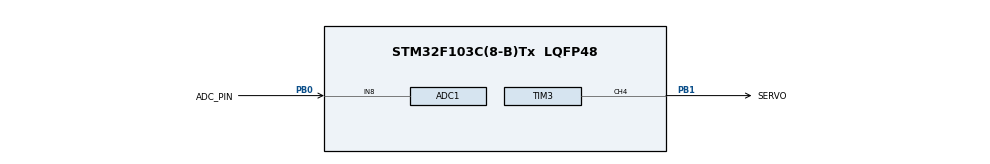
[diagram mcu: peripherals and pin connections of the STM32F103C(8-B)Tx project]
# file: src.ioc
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ADC1.Channel-0\#ChannelRegularConversion=ADC_CHANNEL_8
ADC1.NbrOfConversionFlag=1
ADC1.Rank-0\#ChannelRegularConversion=1
ADC1.SamplingTime-0\#ChannelRegularConversion=ADC_SAMPLETIME_55CYCLES_5
ADC1.master=1
Mcu.Family=STM32F1
Mcu.Name=STM32F103C(8-B)Tx
Mcu.Package=LQFP48
NVIC.PriorityGroup=NVIC_PRIORITYGROUP_4
NVIC.TIM2_IRQn=true\:2\:0\:true\:false\:true\:true\:true\:true
PA13.Mode=Serial_Wire
PA13.Signal=SYS_JTMS-SWDIO
PA14.Mode=Serial_Wire
PA14.Signal=SYS_JTCK-SWCLK
PB0.GPIO_Label=ADC_PIN
PB0.Signal=SharedAnalog_PB0
PB1.GPIO_Label=SERVO
PB1.Signal=S_TIM3_CH4
PD0-OSC_IN.Mode=HSE-External-Oscillator
PD0-OSC_IN.Signal=RCC_OSC_IN
PD1-OSC_OUT.Mode=HSE-External-Oscillator
PD1-OSC_OUT.Signal=RCC_OSC_OUT
ProjectManager.HeapSize=0x200
ProjectManager.StackSize=0x400
ProjectManager.TargetToolchain=EWARM V8.32
RCC.ADCPresc=RCC_ADCPCLK2_DIV6
RCC.AHBFreq_Value=72000000
RCC.APB1CLKDivider=RCC_HCLK_DIV2
RCC.APB1Freq_Value=36000000
RCC.APB1TimFreq_Value=72000000
RCC.APB2Freq_Value=72000000
RCC.APB2TimFreq_Value=72000000
RCC.HCLKFreq_Value=72000000
RCC.PLLMUL=RCC_PLL_MUL9
RCC.PLLSourceVirtual=RCC_PLLSOURCE_HSE
RCC.SYSCLKFreq_VALUE=72000000
RCC.SYSCLKSource=RCC_SYSCLKSOURCE_PLLCLK
RCC.USBFreq_Value=72000000
SH.S_TIM3_CH4.0=TIM3_CH4,PWM Generation4 CH4
SH.SharedAnalog_PB0.0=GPIO_Analog
SH.SharedAnalog_PB0.1=ADC1_IN8,IN8
TIM2.Period=999
TIM2.Prescaler=71
TIM3.AutoReloadPreload=TIM_AUTORELOAD_PRELOAD_ENABLE
TIM3.Channel-PWM\ Generation4\ CH4=TIM_CHANNEL_4
TIM3.OCFastMode_PWM-PWM\ Generation4\ CH4=TIM_OCFAST_ENABLE
TIM3.Period=19999
TIM3.Prescaler=71
TIM3.Pulse-PWM\ Generation4\ CH4=1500
VP_TIM2_VS_ClockSourceINT.Mode=Internal
VP_TIM3_VS_ClockSourceINT.Mode=Internal
board=custom

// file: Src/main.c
  /* USER CODE BEGIN Header */
  /**
    ******************************************************************************
    * @file           : main.c
    * @brief          : Main program body
    ******************************************************************************
    * @attention
    *
    * Copyright (c) 2026 STMicroelectronics.
    * All rights reserved.
    *
    * This software is licensed under terms that can be found in the LICENSE file
    * in the root directory of this software component.
    * If no LICENSE file comes with this software, it is provided AS-IS.
    *
    ******************************************************************************
    */
    #include "display.h"
  /* USER CODE END Header */
  /* Includes ------------------------------------------------------------------*/
  #include "main.h"

  /* Private includes ----------------------------------------------------------*/

  /* Private typedef -----------------------------------------------------------*/

  /* Private define ------------------------------------------------------------*/

  /* Private macro -------------------------------------------------------------*/

  /* Private variables ---------------------------------------------------------*/
  ADC_HandleTypeDef hadc1;

  TIM_HandleTypeDef htim2;
  TIM_HandleTypeDef htim3;

  /* Private function prototypes -----------------------------------------------*/
  void SystemClock_Config(void);
  static void MX_GPIO_Init(void);
  static void MX_ADC1_Init(void);
  static void MX_TIM2_Init(void);
  static void MX_TIM3_Init(void);

  /* Private user code ---------------------------------------------------------*/

  /**
    * @brief  The application entry point.
    * @retval int
    */
  int main(void)
  {

    /* MCU Configuration--------------------------------------------------------*/

    /* Reset of all peripherals, Initializes the Flash interface and the Systick. */
    HAL_Init();

    /* Configure the system clock */
    SystemClock_Config();

    /* Initialize all configured peripherals */
    MX_GPIO_Init();
    MX_ADC1_Init();
    MX_TIM2_Init();
    MX_TIM3_Init();
    /* USER CODE BEGIN 2 */
    HAL_ADCEx_Calibration_Start(&hadc1);
    Display_Init();
    HAL_TIM_Base_Start_IT(&htim2);
    HAL_TIM_PWM_Start(&htim3, TIM_CHANNEL_4);
    /* USER CODE END 2 */

    /* Infinite loop */
    while (1)
    {

      /* USER CODE BEGIN 3 */
      HAL_ADC_Start(&hadc1);
      if (HAL_ADC_PollForConversion(&hadc1, 100) == HAL_OK)
      {
        uint32_t adc_value = HAL_ADC_GetValue(&hadc1);
        uint16_t servo_position = (adc_value * 180) / 4095;
        uint16_t pulse = ((servo_position * 2000) / 180) + 500;

        __HAL_TIM_SET_COMPARE(&htim3, TIM_CHANNEL_4, pulse);
        Display_SetNumber(servo_position);
      }
      HAL_ADC_Stop(&hadc1);
    }
    /* USER CODE END 3 */
  }

  /**
    * @brief System Clock Configuration
    * @retval None
    */
  void SystemClock_Config(void)
  {
    RCC_OscInitTypeDef RCC_OscInitStruct = {0};
    RCC_ClkInitTypeDef RCC_ClkInitStruct = {0};
    RCC_PeriphCLKInitTypeDef PeriphClkInit = {0};

    /** Initializes the RCC Oscillators according to the specified parameters
    * in the RCC_OscInitTypeDef structure.
    */
    RCC_OscInitStruct.OscillatorType = RCC_OSCILLATORTYPE_HSE;
    RCC_OscInitStruct.HSEState = RCC_HSE_ON;
    RCC_OscInitStruct.HSEPredivValue = RCC_HSE_PREDIV_DIV1;
    RCC_OscInitStruct.HSIState = RCC_HSI_ON;
    RCC_OscInitStruct.PLL.PLLState = RCC_PLL_ON;
    RCC_OscInitStruct.PLL.PLLSource = RCC_PLLSOURCE_HSE;
    RCC_OscInitStruct.PLL.PLLMUL = RCC_PLL_MUL9;
    if (HAL_RCC_OscConfig(&RCC_OscInitStruct) != HAL_OK)
    {
      Error_Handler();
    }

    /** Initializes the CPU, AHB and APB buses clocks
    */
    RCC_ClkInitStruct.ClockType = RCC_CLOCKTYPE_HCLK|RCC_CLOCKTYPE_SYSCLK
                                |RCC_CLOCKTYPE_PCLK1|RCC_CLOCKTYPE_PCLK2;
    RCC_ClkInitStruct.SYSCLKSource = RCC_SYSCLKSOURCE_PLLCLK;
    RCC_ClkInitStruct.AHBCLKDivider = RCC_SYSCLK_DIV1;
    RCC_ClkInitStruct.APB1CLKDivider = RCC_HCLK_DIV2;
    RCC_ClkInitStruct.APB2CLKDivider = RCC_HCLK_DIV1;

    if (HAL_RCC_ClockConfig(&RCC_ClkInitStruct, FLASH_LATENCY_2) != HAL_OK)
    {
      Error_Handler();
    }
    PeriphClkInit.PeriphClockSelection = RCC_PERIPHCLK_ADC;
    PeriphClkInit.AdcClockSelection = RCC_ADCPCLK2_DIV6;
    if (HAL_RCCEx_PeriphCLKConfig(&PeriphClkInit) != HAL_OK)
    {
      Error_Handler();
    }
  }

  /**
    * @brief ADC1 Initialization Function
    * @param None
    * @retval None
    */
  static void MX_ADC1_Init(void)
  {

    ADC_ChannelConfTypeDef sConfig = {0};

    /** Common config
    */
    hadc1.Instance = ADC1;
    hadc1.Init.ScanConvMode = ADC_SCAN_DISABLE;
    hadc1.Init.ContinuousConvMode = DISABLE;
    hadc1.Init.DiscontinuousConvMode = DISABLE;
    hadc1.Init.ExternalTrigConv = ADC_SOFTWARE_START;
    hadc1.Init.DataAlign = ADC_DATAALIGN_RIGHT;
    hadc1.Init.NbrOfConversion = 1;
    if (HAL_ADC_Init(&hadc1) != HAL_OK)
    {
      Error_Handler();
    }

    /** Configure Regular Channel
    */
    sConfig.Channel = ADC_CHANNEL_8;
    sConfig.Rank = ADC_REGULAR_RANK_1;
    sConfig.SamplingTime = ADC_SAMPLETIME_55CYCLES_5;
    if (HAL_ADC_ConfigChannel(&hadc1, &sConfig) != HAL_OK)
    {
      Error_Handler();
    }

  }

  /**
    * @brief TIM2 Initialization Function
    * @param None
    * @retval None
    */
  static void MX_TIM2_Init(void)
  {

    TIM_ClockConfigTypeDef sClockSourceConfig = {0};
    TIM_MasterConfigTypeDef sMasterConfig = {0};

    htim2.Instance = TIM2;
    htim2.Init.Prescaler = 71;
    htim2.Init.CounterMode = TIM_COUNTERMODE_UP;
    htim2.Init.Period = 999;
    htim2.Init.ClockDivision = TIM_CLOCKDIVISION_DIV1;
    htim2.Init.AutoReloadPreload = TIM_AUTORELOAD_PRELOAD_DISABLE;
    if (HAL_TIM_Base_Init(&htim2) != HAL_OK)
    {
      Error_Handler();
    }
    sClockSourceConfig.ClockSource = TIM_CLOCKSOURCE_INTERNAL;
    if (HAL_TIM_ConfigClockSource(&htim2, &sClockSourceConfig) != HAL_OK)
    {
      Error_Handler();
    }
    sMasterConfig.MasterOutputTrigger = TIM_TRGO_RESET;
    sMasterConfig.MasterSlaveMode = TIM_MASTERSLAVEMODE_DISABLE;
    if (HAL_TIMEx_MasterConfigSynchronization(&htim2, &sMasterConfig) != HAL_OK)
    {
      Error_Handler();
    }

  }

  /**
    * @brief TIM3 Initialization Function
    * @param None
    * @retval None
    */
  static void MX_TIM3_Init(void)
  {

    TIM_ClockConfigTypeDef sClockSourceConfig = {0};
    TIM_MasterConfigTypeDef sMasterConfig = {0};
    TIM_OC_InitTypeDef sConfigOC = {0};

    htim3.Instance = TIM3;
    htim3.Init.Prescaler = 71;
    htim3.Init.CounterMode = TIM_COUNTERMODE_UP;
    htim3.Init.Period = 19999;
    htim3.Init.ClockDivision = TIM_CLOCKDIVISION_DIV1;
    htim3.Init.AutoReloadPreload = TIM_AUTORELOAD_PRELOAD_ENABLE;
    if (HAL_TIM_Base_Init(&htim3) != HAL_OK)
    {
      Error_Handler();
    }
    sClockSourceConfig.ClockSource = TIM_CLOCKSOURCE_INTERNAL;
    if (HAL_TIM_ConfigClockSource(&htim3, &sClockSourceConfig) != HAL_OK)
    {
      Error_Handler();
    }
    if (HAL_TIM_PWM_Init(&htim3) != HAL_OK)
    {
      Error_Handler();
    }
    sMasterConfig.MasterOutputTrigger = TIM_TRGO_RESET;
    sMasterConfig.MasterSlaveMode = TIM_MASTERSLAVEMODE_DISABLE;
    if (HAL_TIMEx_MasterConfigSynchronization(&htim3, &sMasterConfig) != HAL_OK)
    {
      Error_Handler();
    }
    sConfigOC.OCMode = TIM_OCMODE_PWM1;
    sConfigOC.Pulse = 1500;
    sConfigOC.OCPolarity = TIM_OCPOLARITY_HIGH;
    sConfigOC.OCFastMode = TIM_OCFAST_ENABLE;
    if (HAL_TIM_PWM_ConfigChannel(&htim3, &sConfigOC, TIM_CHANNEL_4) != HAL_OK)
    {
      Error_Handler();
    }
    HAL_TIM_MspPostInit(&htim3);

  }

  /**
    * @brief GPIO Initialization Function
    * @param None
    * @retval None
    */
  static void MX_GPIO_Init(void)
  {

    /* GPIO Ports Clock Enable */
    __HAL_RCC_GPIOD_CLK_ENABLE();
    __HAL_RCC_GPIOB_CLK_ENABLE();
    __HAL_RCC_GPIOA_CLK_ENABLE();

  }

  /* USER CODE BEGIN 4 */
  void HAL_TIM_PeriodElapsedCallback(TIM_HandleTypeDef *htim)
  {
      if (htim->Instance == TIM2)
      {
        // your periodic action here
        Display_Refresh();
      }
  }
  /* USER CODE END 4 */

  /**
    * @brief  This function is executed in case of error occurrence.
    * @retval None
    */
  void Error_Handler(void)
  {
    __disable_irq();
    while (1)
    {
    }
  }
  #ifdef USE_FULL_ASSERT
  /**
    * @brief  Reports the name of the source file and the source line number
    *         where the assert_param error has occurred.
    * @param  file: pointer to the source file name
    * @param  line: assert_param error line source number
    * @retval None
    */
  void assert_failed(uint8_t *file, uint32_t line)
  {
  }
  #endif /* USE_FULL_ASSERT */
